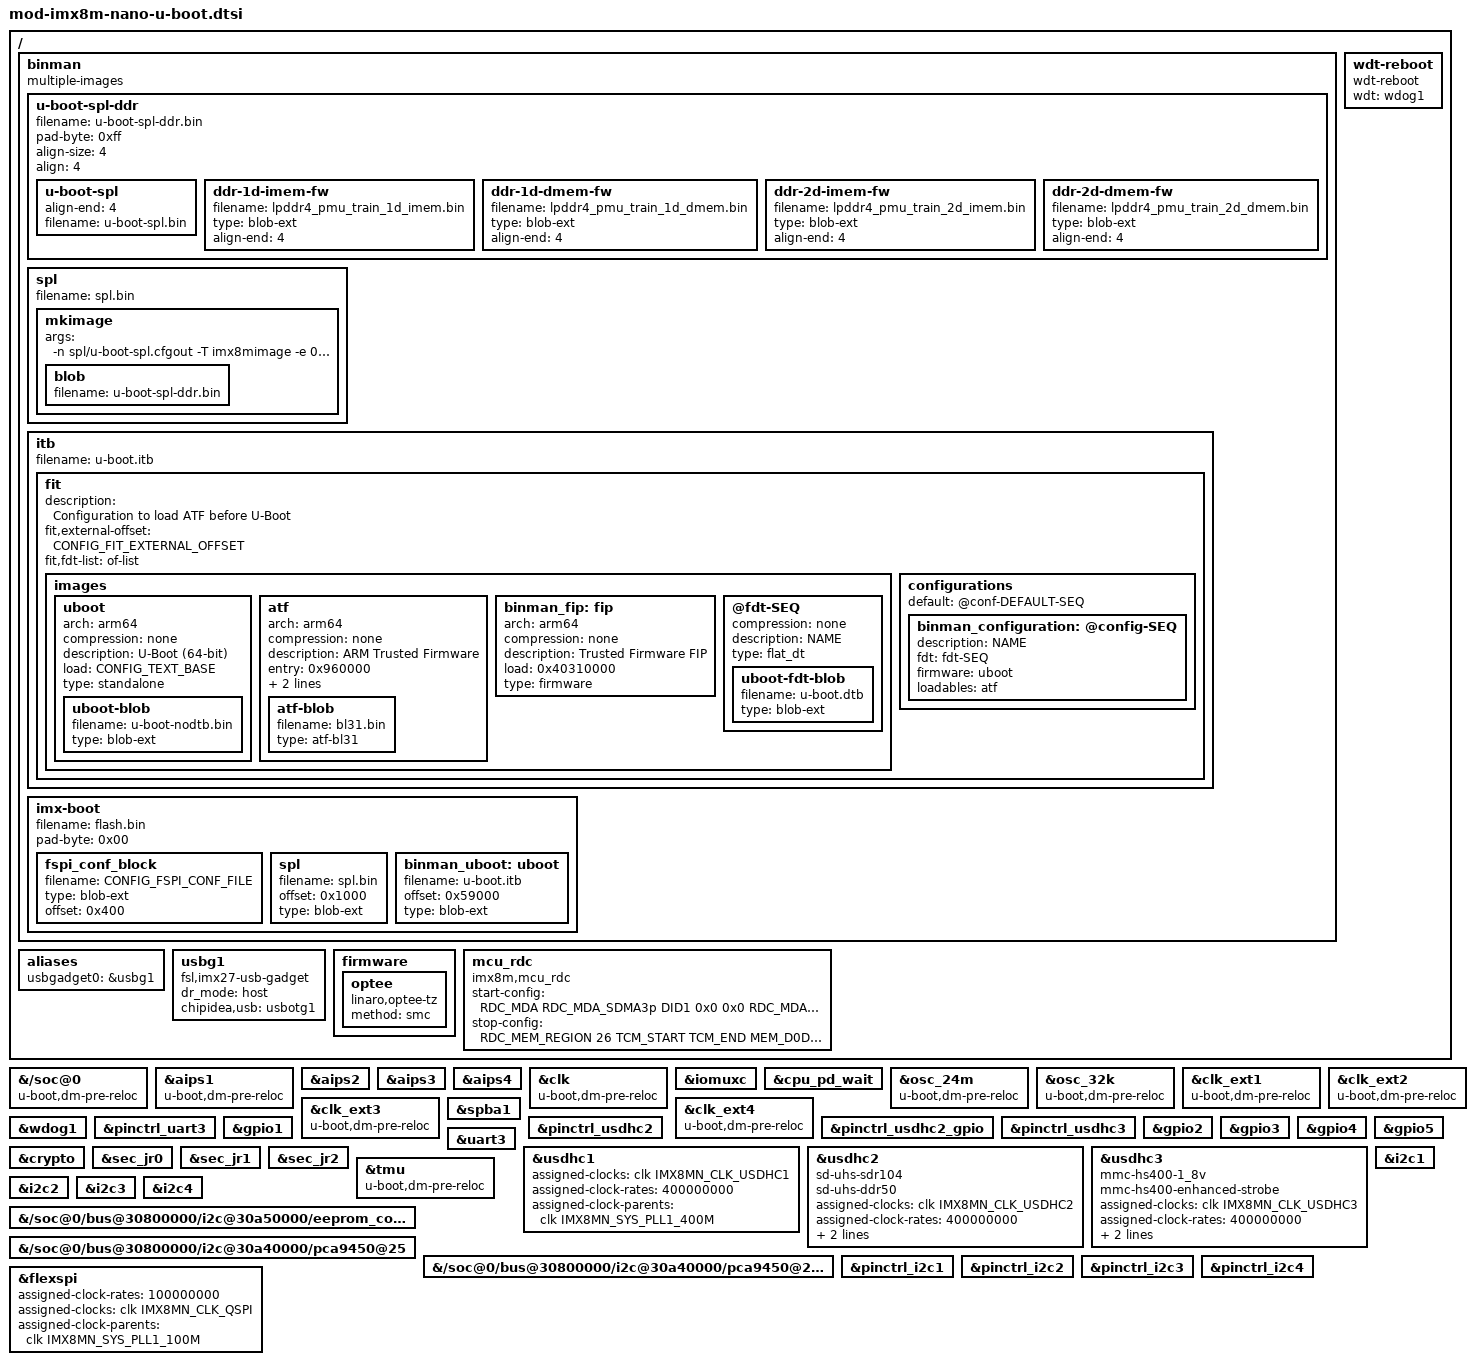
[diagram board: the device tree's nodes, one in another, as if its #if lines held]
// SPDX-License-Identifier: GPL-2.0+
/*
 * Copyright 2019 NXP
 */
#include "imx8mn-sec-def.h"

/ {
	binman: binman {
		multiple-images;
	};

	wdt-reboot {
		compatible = "wdt-reboot";
		wdt = <&wdog1>;
		u-boot,dm-spl;
	};

	aliases {
		usbgadget0 = &usbg1;
	};

	usbg1: usbg1 {
		compatible = "fsl,imx27-usb-gadget";
		dr_mode = "host";
		chipidea,usb = <&usbotg1>;
		status = "okay";
	};

	firmware {
		optee {
			compatible = "linaro,optee-tz";
			method = "smc";
		};
	};
	mcu_rdc {
		compatible = "imx8m,mcu_rdc";
			    /* rdc config when MCU starts
			     * master
			     *   SDMA3p --> domain 1
			     *   SDMA3b --> domian 1
			     *   SDMA3_SPBA2  --> domian 1
			     * peripheral:
			     *   UART4  --> Only Domian 1 can access
			     * memory:
			     *   TCM    --> Only Domian 1 can access (0x7E0000~0x81FFFF)
			     *   DDR    --> Only Domian 1 can access (0x80000000~0x81000000)
			     * end.
			     */
		start-config = <
			    RDC_MDA  RDC_MDA_SDMA3p DID1 0x0 0x0
			    RDC_MDA  RDC_MDA_SDMA3b DID1 0x0 0x0
			    RDC_MDA  RDC_MDA_SDMA3_SPBA2 DID1 0x0 0x0
			    RDC_PDAP RDC_PDAP_UART4 PDAP_D1_ACCESS 0x0 0x0
			    RDC_MEM_REGION 26 TCM_START TCM_END MEM_D1_ACCESS
			    RDC_MEM_REGION 0 M4_EVK_DDR3L_START M4_EVK_DDR3L_END MEM_D1_ACCESS
			    0x0      0x0            0x0  0x0 0x0
			  >;
			    /* rdc config when MCU stops
			     * memory:
			     *   TCM    --> domain 0/1 can access (0x7E0000~0x81FFFF)
			     *   DDR    --> domain 0/1 can access (0x80000000~0x81000000)
			     * end.
			     */
		stop-config = <
			    RDC_MEM_REGION 26 TCM_START TCM_END MEM_D0D1_ACCESS
			    RDC_MEM_REGION 0 M4_EVK_DDR3L_START M4_EVK_DDR3L_END MEM_D0D1_ACCESS
			    0x0      0x0            0x0  0x0 0x0
			  >;
	};
};

&{/soc@0} {
	u-boot,dm-pre-reloc;
	u-boot,dm-spl;
};

&aips1 {
	u-boot,dm-spl;
	u-boot,dm-pre-reloc;
};

&aips2 {
	u-boot,dm-spl;
};

&aips3 {
	u-boot,dm-spl;
};

&aips4 {
	u-boot,dm-spl;
};

&clk {
	u-boot,dm-spl;
	u-boot,dm-pre-reloc;
	/delete-property/ assigned-clocks;
	/delete-property/ assigned-clock-parents;
	/delete-property/ assigned-clock-rates;
};

&iomuxc {
	u-boot,dm-spl;
};

&cpu_pd_wait {
	/delete-property/ compatible;
};

&osc_24m {
	u-boot,dm-spl;
	u-boot,dm-pre-reloc;
};

&osc_32k {
	u-boot,dm-spl;
	u-boot,dm-pre-reloc;
};

&clk_ext1 {
	u-boot,dm-spl;
	u-boot,dm-pre-reloc;
};

&clk_ext2 {
	u-boot,dm-spl;
	u-boot,dm-pre-reloc;
};

&clk_ext3 {
	u-boot,dm-spl;
	u-boot,dm-pre-reloc;
};

&clk_ext4 {
	u-boot,dm-spl;
	u-boot,dm-pre-reloc;
};

&spba1 {
	u-boot,dm-spl;
};

&wdog1 {
	u-boot,dm-spl;
};

&pinctrl_uart3 {
	u-boot,dm-spl;
};

&pinctrl_usdhc2_gpio {
	u-boot,dm-spl;
};

&pinctrl_usdhc2 {
	u-boot,dm-spl;
};

&pinctrl_usdhc3 {
	u-boot,dm-spl;
};

&gpio1 {
	u-boot,dm-spl;
};

&gpio2 {
	u-boot,dm-spl;
};

&gpio3 {
	u-boot,dm-spl;
};

&gpio4 {
	u-boot,dm-spl;
};

&gpio5 {
	u-boot,dm-spl;
};

&uart3 {
	u-boot,dm-spl;
};

&crypto {
	u-boot,dm-spl;
};

&sec_jr0 {
	u-boot,dm-spl;
};

&sec_jr1 {
	u-boot,dm-spl;
};

&sec_jr2 {
	u-boot,dm-spl;
};

&usdhc1 {
	u-boot,dm-spl;
	assigned-clocks = <&clk IMX8MN_CLK_USDHC1>;
	assigned-clock-rates = <400000000>;
	assigned-clock-parents = <&clk IMX8MN_SYS_PLL1_400M>;
};

&usdhc2 {
	u-boot,dm-spl;
	sd-uhs-sdr104;
	sd-uhs-ddr50;
	assigned-clocks = <&clk IMX8MN_CLK_USDHC2>;
	assigned-clock-rates = <400000000>;
	assigned-clock-parents = <&clk IMX8MN_SYS_PLL1_400M>;
};

&usdhc3 {
	u-boot,dm-spl;
	mmc-hs400-1_8v;
	mmc-hs400-enhanced-strobe;
	assigned-clocks = <&clk IMX8MN_CLK_USDHC3>;
	assigned-clock-rates = <400000000>;
	assigned-clock-parents = <&clk IMX8MN_SYS_PLL1_400M>;
};

&tmu {
  u-boot,dm-pre-reloc;
};

&i2c1 {
	u-boot,dm-spl;
};

&i2c2 {
	u-boot,dm-spl;
};

&i2c3 {
	u-boot,dm-spl;
};

&i2c4 {
	u-boot,dm-spl;
};

&{/soc@0/bus@30800000/i2c@30a50000/eeprom_config@50} {
    u-boot,dm-spl;
};

&{/soc@0/bus@30800000/i2c@30a40000/pca9450@25} {
	u-boot,dm-spl;
};

&{/soc@0/bus@30800000/i2c@30a40000/pca9450@25/regulators} {
	u-boot,dm-spl;
};

&pinctrl_i2c1 {
	u-boot,dm-spl;
};

&pinctrl_i2c2 {
	u-boot,dm-spl;
};

&pinctrl_i2c3 {
	u-boot,dm-spl;
};

&pinctrl_i2c4 {
	u-boot,dm-spl;
};

&flexspi {
	assigned-clock-rates = <100000000>;
	assigned-clocks = <&clk IMX8MN_CLK_QSPI>;
	assigned-clock-parents = <&clk IMX8MN_SYS_PLL1_100M>;
};

&binman {
	 u-boot-spl-ddr {
		filename = "u-boot-spl-ddr.bin";
		pad-byte = <0xff>;
	    align-size = <4>;
		align = <4>;

		u-boot-spl {
			align-end = <4>;
            filename = "u-boot-spl.bin";
		};

		ddr-1d-imem-fw {
			filename = "lpddr4_pmu_train_1d_imem.bin";
			type = "blob-ext";
			align-end = <4>;
		};

		ddr-1d-dmem-fw {
			filename = "lpddr4_pmu_train_1d_dmem.bin";
			type = "blob-ext";
			align-end = <4>;
		};

		ddr-2d-imem-fw {
			filename = "lpddr4_pmu_train_2d_imem.bin";
			type = "blob-ext";
			align-end = <4>;
		};

		ddr-2d-dmem-fw {
			filename = "lpddr4_pmu_train_2d_dmem.bin";
			type = "blob-ext";
			align-end = <4>;
		};
	};

	spl {
        filename = "spl.bin";

		mkimage {
			args = "-n spl/u-boot-spl.cfgout -T imx8mimage -e 0x912000";

			blob {
				filename = "u-boot-spl-ddr.bin";
			};
		};
	};

	itb {
		filename = "u-boot.itb";

		fit {
			description = "Configuration to load ATF before U-Boot";
			fit,external-offset = <CONFIG_FIT_EXTERNAL_OFFSET>;
            fit,fdt-list = "of-list";
			#address-cells = <1>;

			images {
				uboot {
					arch = "arm64";
					compression = "none";
					description = "U-Boot (64-bit)";
				    load = <CONFIG_TEXT_BASE>;
					type = "standalone";

					uboot-blob {
						filename = "u-boot-nodtb.bin";
                        type = "blob-ext";
					};
				};

				atf {
					arch = "arm64";
					compression = "none";
					description = "ARM Trusted Firmware";
					entry = <0x960000>;
					load = <0x960000>;
					type = "firmware";

					atf-blob {
						filename = "bl31.bin";
                        type = "atf-bl31";
					};
				};

				binman_fip: fip {
					arch = "arm64";
					compression = "none";
					description = "Trusted Firmware FIP";
					load = <0x40310000>;
					type = "firmware";
				};

				@fdt-SEQ {
					compression = "none";
					description = "NAME";
					type = "flat_dt";

					uboot-fdt-blob {
						filename = "u-boot.dtb";
                        type = "blob-ext";
					};
				};
			};

			configurations {
				default = "@conf-DEFAULT-SEQ";

				binman_configuration: @config-SEQ {
					description = "NAME";
					fdt = "fdt-SEQ";
					firmware = "uboot";
					loadables = "atf";
				};
			};
		};
	};

    imx-boot {
      filename = "flash.bin";
      pad-byte = <0x00>;

#ifdef CONFIG_FSPI_CONF_HEADER
		fspi_conf_block {
			filename = CONFIG_FSPI_CONF_FILE;
			type = "blob-ext";
			offset = <0x400>;
		};

		spl {
			filename = "spl.bin";
			offset = <0x1000>;
			type = "blob-ext";
		};

		binman_uboot: uboot {
			filename = "u-boot.itb";
			offset = <0x59000>;
			type = "blob-ext";
		};
#else

		spl {
			offset = <0x0>;
			filename = "spl.bin";
			type = "blob-ext";
		};

		binman_uboot: uboot {
			offset = <0x58000>;
			filename = "u-boot.itb";
			type = "blob-ext";
		};
#endif
    };
};


